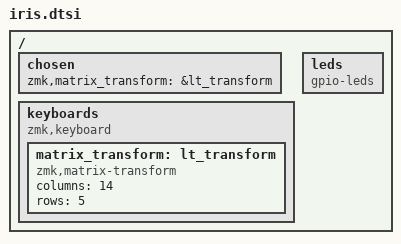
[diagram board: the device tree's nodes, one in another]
// Generic Split Keyboard Common Configuration
#include <dt-bindings/gpio/gpio.h>
#include <dt-bindings/zmk/keys.h>

/ {
    chosen {
        zmk,matrix_transform = &lt_transform;
    };

    keyboards {
        compatible = "zmk,keyboard";

        matrix_transform: lt_transform {
            compatible = "zmk,matrix-transform";
            columns = <14>;
            rows = <5>;
            // Define your key matrix layout here
        };
    };

    leds {
        compatible = "gpio-leds";
        // Define any LEDs here
    };

    // Define other peripherals (e.g., OLED display) here
};
